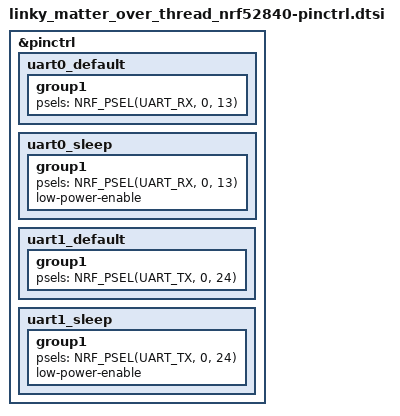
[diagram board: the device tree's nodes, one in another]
/*
 * SPDX-License-Identifier: Apache-2.0
 */

&pinctrl {
	/* TIC data, from the AO3400A drain (10 k pull-up on the board). Receive only. */
	uart0_default: uart0_default {
		group1 {
			psels = <NRF_PSEL(UART_RX, 0, 13)>;
		};
	};

	uart0_sleep: uart0_sleep {
		group1 {
			psels = <NRF_PSEL(UART_RX, 0, 13)>;
			low-power-enable;
		};
	};

	/* Debug output on J2 pin 4. Transmit only. */
	uart1_default: uart1_default {
		group1 {
			psels = <NRF_PSEL(UART_TX, 0, 24)>;
		};
	};

	uart1_sleep: uart1_sleep {
		group1 {
			psels = <NRF_PSEL(UART_TX, 0, 24)>;
			low-power-enable;
		};
	};
};
